# SYSTICK register map
Vendor: Texas Instruments
Peripheral module from a debugger description file (folder CC23x0R5).
Registers are 32-bit, access per field, reset 0x0 unless marked. A register's access mark holds for its fields unless they carry their own. Offsets are as the file gives them; lines under a group give offsets from that group; [hi:lo] are bit positions; {n}, {i} and the like mark numbered series; 'fields as' and 'values as' point back to an identical list; <NAME> marks a mode.

## SYSTICK
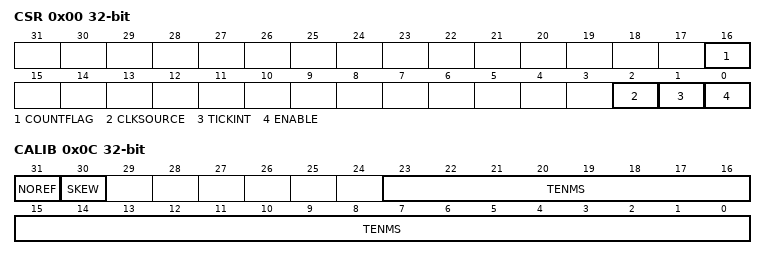
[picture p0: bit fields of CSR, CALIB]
0x00 CSR — SysTick Control and Status Register Use the SysTick Control and Status Register to enable the SysTick features.
  [16] COUNTFLAG ro — Returns 1 if timer counted to 0 since last time this was read. Clears on read by application or debugger.
  [2] CLKSOURCE ro — SysTick clock source. Always reads as one if STCALIB reports NOREF. 0x0:Systick driven by external reference clock. 0x1:Systick driven by processor clock
  [1] TICKINT rw — 0x0:Counting down to zero does not pend the systick handler. software can use countflag to determine if the systick handler has ever counted to zero. 0x1:Counting down to zero pends the systick handler.
  [0] ENABLE rw — Enable SysTick counter 0x0:Counter disabled 0x1:Counter operates in a multi-shot way. that is, counter loads with the reload value and then begins counting down. on reaching 0, it sets the countflag to 1 and optionally pends the systick handler, based on tickint. it then loads the reload value again, and begins counting.
0x04 RVR — SysTick Reload Value Register Use the SysTick Reload Value Register to specify the start value to load into the current value register when the counter reaches 0. It can be any value between 0 and 0x00FFFFFF. A start value of 0 is possible, but has no effect because the SysTick interrupt and COUNTFLAG are activated when counting from 1 to 0. The reset value of this register is UNKNOWN.
  [23:0] RELOAD rw — Value to load into the SysTick Current Value Register when the counter reaches 0.
0x08 CVR — SysTick Current Value Register Use the SysTick Current Value Register to find the current value in the register. The reset value of this register is UNKNOWN.
  [23:0] CURRENT rw — Reads return the current value of the SysTick counter. This register is write-clear. Writing to it with any value clears the register to 0. Clearing this register also clears the COUNTFLAG bit of the SysTick Control and Status Register.
0x0C CALIB ro — SysTick Calibration Value Register Use the SysTick Calibration Value Register to enable software to scale to any required speed using divide and multiply.
  [31] NOREF — If reads as 1, the Reference clock is not provided - the CLKSOURCE bit of the SysTick Control and Status register will be forced to 1 and cannot be cleared to 0.
  [30] SKEW — If reads as 1, the calibration value for 10ms is inexact (due to clock frequency).
  [23:0] TENMS — An optional Reload value to be used for 10ms (100Hz) timing, subject to system clock skew errors. If the value reads as 0, the calibration value is not known.
